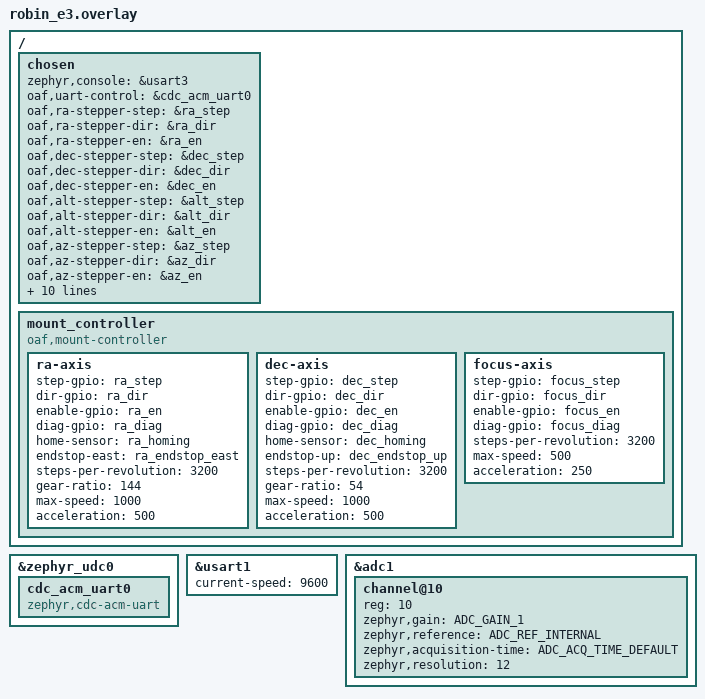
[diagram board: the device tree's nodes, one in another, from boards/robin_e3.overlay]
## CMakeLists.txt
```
cmake_minimum_required(VERSION 3.20.0)

find_package(Zephyr REQUIRED HINTS $ENV{ZEPHYR_BASE})
project(OpenAstroFirmware)

add_subdirectory_ifdef(CONFIG_MOUNT src/mount)

target_sources(app PRIVATE src/main.cpp)
```

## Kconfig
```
module = APP
module-str = app
source "subsys/logging/Kconfig.template.log_config"

rsource "src/mount/Kconfig"

menu "Zephyr"
source "Kconfig.zephyr"
endmenu
```

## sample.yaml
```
# This file is provided so that the application can be compiled using Twister,
# the Zephyr testing tool. In this file, multiple combinations can be specified,
# so that you can easily test all of them locally or in CI.
sample:
  description: OpenAstroFirmware
  name: openastrofirmware
common:
  build_only: true
  integration_platforms:
    - robin_nano
    - robin_e3
    - native_sim
tests:
  app.default: {}
  app.debug:
    extra_overlay_confs:
      - debug.conf
```

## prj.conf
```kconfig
# Disable zephyr log message at the beginning of the boot process
CONFIG_BOOT_BANNER=n

# C++ support
CONFIG_CPP=y
CONFIG_STD_CPP20=y
CONFIG_REQUIRES_FULL_LIBCPP=y

# GPIO support
CONFIG_GPIO=y

# CONFIG_RING_BUFFER=y
CONFIG_LX200=y

# CONFIG_TIMING_FUNCTIONS=y
CONFIG_MAIN_THREAD_PRIORITY=5

CONFIG_MAIN_STACK_SIZE=4096
CONFIG_HEAP_MEM_POOL_SIZE=4096

# Enable zephyr bus
CONFIG_ZBUS=y
CONFIG_ZBUS_MSG_SUBSCRIBER=y

# Stepper
# CONFIG_POLL=y
# CONFIG_COUNTER=y
# CONFIG_STEPPER=y
# CONFIG_STEP_DIR_STEPPER_COUNTER_TIMING=y

### Logging

CONFIG_LOG=y
CONFIG_LOG_BACKEND_UART=y
CONFIG_LOG_MODE_DEFERRED=y
# CONFIG_LOG_MODE_IMMEDIATE=y

# Default log level (including zephyr)
CONFIG_LOG_DEFAULT_LEVEL=3

# Serial
CONFIG_SERIAL=y

# Console
CONFIG_CONSOLE=y
# CONFIG_CONSOLE_SUBSYS=y
# CONFIG_CONSOLE_GETCHAR=y
# CONFIG_CONSOLE_GETCHAR_BUFSIZE=64
# CONFIG_CONSOLE_PUTCHAR_BUFSIZE=512

CONFIG_LOG_THREAD_ID_PREFIX=y

# Enables runtime filtering for logging.
# This allows the logging level to be changed at runtime,
# providing flexibility for debugging and monitoring.
# CONFIG_LOG_RUNTIME_FILTERING=y
# CONFIG_LOG_BUFFER_SIZE=4096
# CONFIG_LOG_PRINTK=y
# CONFIG_LOG_PROCESS_TRIGGER_THRESHOLD=0
# CONFIG_LOG_TAG_MAX_LEN=8

# Thread analyzer
# CONFIG_THREAD_ANALYZER=y
# CONFIG_THREAD_ANALYZER_USE_PRINTK=y 
# CONFIG_THREAD_ANALYZER_AUTO=y
# CONFIG_THREAD_ANALYZER_AUTO_INTERVAL=5

# Enable fault handling
# CONFIG_FAULT_DUMP=2
# CONFIG_EXCEPTION_STACK_TRACE=y
# CONFIG_DEBUG_COREDUMP=y 
# CONFIG_DEBUG_COREDUMP_BACKEND_LOGGING=y
# CONFIG_DEBUG_COREDUMP_MEMORY_DUMP_MIN=y
```

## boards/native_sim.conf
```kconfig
CONFIG_SERIAL=y

# CONFIG_UART_CONSOLE=y

# Enable the native POSIX UART driver backend
CONFIG_UART_NATIVE_POSIX=y

# Console (logs) will be on stdout
# CONFIG_UART_NATIVE_PTY_0_ON_STDINOUT=y
# CONFIG_NATIVE_UART_0_ON_STDINOUT=y

# Enable UART for control (e.g. lx200)
CONFIG_UART_NATIVE_POSIX_PORT_1_ENABLE=y
```

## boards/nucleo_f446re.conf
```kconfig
CONFIG_SYS_CLOCK_HW_CYCLES_PER_SEC=180000000
CONFIG_CORTEX_M_SYSTICK=y

CONFIG_UART_INTERRUPT_DRIVEN=y
CONFIG_UART_USE_RUNTIME_CONFIGURE=y

# CONFIG_USB_DEVICE_STACK=y
# CONFIG_USB_DEVICE_INITIALIZE_AT_BOOT=n
# CONFIG_USB_DEVICE_VID=0x1209
# CONFIG_USB_DEVICE_PID=0x0AF0
# CONFIG_USB_DEVICE_PRODUCT="OpenAstroFirmware"
# CONFIG_USB_DEVICE_MANUFACTURER="OpenAstroTech"

# CONFIG_USB_CDC_ACM=y
# CONFIG_USB_CDC_ACM_RINGBUF_SIZE=512

# CONFIG_USB_COMPOSITE_DEVICE=y

# # CONFIG_USB_DEVICE_LOG_LEVEL_INF=y
# # CONFIG_USB_DRIVER_LOG_LEVEL_INF=y
# CONFIG_USB_CDC_ACM_LOG_LEVEL_OFF=y
```

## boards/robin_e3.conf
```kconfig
CONFIG_SYS_CLOCK_HW_CYCLES_PER_SEC=72000000
CONFIG_CORTEX_M_SYSTICK=y

CONFIG_USB_DEVICE_STACK=y
CONFIG_USB_DEVICE_INITIALIZE_AT_BOOT=n
CONFIG_USB_DEVICE_VID=0x1209
CONFIG_USB_DEVICE_PID=0x0AF0
CONFIG_USB_DEVICE_PRODUCT="OpenAstroFirmware"
CONFIG_USB_DEVICE_MANUFACTURER="OpenAstroTech"

CONFIG_USB_CDC_ACM=y
CONFIG_USB_CDC_ACM_RINGBUF_SIZE=512

CONFIG_USB_COMPOSITE_DEVICE=y

# CONFIG_USB_DEVICE_LOG_LEVEL_INF=y
# CONFIG_USB_DRIVER_LOG_LEVEL_INF=y
CONFIG_USB_CDC_ACM_LOG_LEVEL_OFF=y
```

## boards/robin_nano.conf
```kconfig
CONFIG_SYS_CLOCK_HW_CYCLES_PER_SEC=168000000
CONFIG_CORTEX_M_SYSTICK=y

CONFIG_USB_DEVICE_STACK=y
CONFIG_USB_DEVICE_INITIALIZE_AT_BOOT=n
CONFIG_USB_DEVICE_VID=0x1209
CONFIG_USB_DEVICE_PID=0x0AF0
CONFIG_USB_DEVICE_PRODUCT="OpenAstroFirmware"
CONFIG_USB_DEVICE_MANUFACTURER="OpenAstroTech"

CONFIG_USB_CDC_ACM=y
CONFIG_USB_CDC_ACM_RINGBUF_SIZE=512

CONFIG_USB_COMPOSITE_DEVICE=y

# CONFIG_USB_DEVICE_LOG_LEVEL_INF=y
# CONFIG_USB_DRIVER_LOG_LEVEL_INF=y
CONFIG_USB_CDC_ACM_LOG_LEVEL_OFF=y
```

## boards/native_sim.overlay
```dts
/ {
    chosen {
        zephyr,console = &uart0;
        oaf,uart-control = &uart1;
    };
};

&uart0 {
    status = "okay";
};

&uart1 {
    status = "okay";
};
```

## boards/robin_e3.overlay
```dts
/ {
    chosen {
        // Console and control interfaces
        zephyr,console = &usart3; 
        oaf,uart-control = &cdc_acm_uart0;
        
        // OpenAstroFirmware specific device mappings
        oaf,ra-stepper-step = &ra_step;
        oaf,ra-stepper-dir = &ra_dir;
        oaf,ra-stepper-en = &ra_en;
        oaf,dec-stepper-step = &dec_step;
        oaf,dec-stepper-dir = &dec_dir;
        oaf,dec-stepper-en = &dec_en;
        oaf,alt-stepper-step = &alt_step;
        oaf,alt-stepper-dir = &alt_dir;
        oaf,alt-stepper-en = &alt_en;
        oaf,az-stepper-step = &az_step;
        oaf,az-stepper-dir = &az_dir;
        oaf,az-stepper-en = &az_en;
        oaf,focus-stepper-step = &focus_step;
        oaf,focus-stepper-dir = &focus_dir;
        oaf,focus-stepper-en = &focus_en;
        
        // Sensor mappings
        oaf,ra-home-sensor = &ra_homing;
        oaf,dec-home-sensor = &dec_homing;
        oaf,ra-endstop-east = &ra_endstop_east;
        oaf,dec-endstop-up = &dec_endstop_up;
        
        
        // Communication interfaces
        oaf,gps-uart = &usart1;
        oaf,external-i2c = &i2c1;
        
        // Status LED
        oaf,status-led = &status_led;
    };

    /* Mount Control Configuration */
    mount_controller {
        compatible = "oaf,mount-controller";
        
        /* RA Axis Configuration */
        ra-axis {
            step-gpio = <&ra_step>;
            dir-gpio = <&ra_dir>;
            enable-gpio = <&ra_en>;
            diag-gpio = <&ra_diag>;
            home-sensor = <&ra_homing>;
            endstop-east = <&ra_endstop_east>;
            
            steps-per-revolution = <3200>;
            gear-ratio = <144>;
            max-speed = <1000>;
            acceleration = <500>;
        };
        
        /* DEC Axis Configuration */
        dec-axis {
            step-gpio = <&dec_step>;
            dir-gpio = <&dec_dir>;
            enable-gpio = <&dec_en>;
            diag-gpio = <&dec_diag>;
            home-sensor = <&dec_homing>;
            endstop-up = <&dec_endstop_up>;
            
            steps-per-revolution = <3200>;
            gear-ratio = <54>;
            max-speed = <1000>;
            acceleration = <500>;
        };
        
        /* Focus/Alt Configuration */
        focus-axis {
            step-gpio = <&focus_step>;
            dir-gpio = <&focus_dir>;
            enable-gpio = <&focus_en>;
            diag-gpio = <&focus_diag>;
            
            steps-per-revolution = <3200>;
            max-speed = <500>;
            acceleration = <250>;
        };
        
        status = "okay";
    };

};

// Configuration for the CDC ACM UART
&zephyr_udc0 {
    cdc_acm_uart0: cdc_acm_uart0 {
        compatible = "zephyr,cdc-acm-uart";
    };
};

// GPS UART configuration
&usart1 {
    current-speed = <9600>;
    status = "okay";
};

// Additional ADC channel for LCD keypad
&adc1 {
    #address-cells = <1>;
    #size-cells = <0>;
    
    channel@10 {
        reg = <10>;
        zephyr,gain = "ADC_GAIN_1";
        zephyr,reference = "ADC_REF_INTERNAL";
        zephyr,acquisition-time = <ADC_ACQ_TIME_DEFAULT>;
        zephyr,resolution = <12>;
    };
};
```

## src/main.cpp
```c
#include <zephyr/kernel.h>
#include <zephyr/logging/log.h>

#include <mount/Mount.hpp>

LOG_MODULE_REGISTER(main, CONFIG_APP_LOG_LEVEL);

// Mount
Mount mount;

int main()
{

	// ReSharper disable CppDFAEndlessLoop
	while (true)
	// ReSharper restore CppDFAEndlessLoop
	{
		k_sleep(K_MSEC(100));
	}

	return 0;
}
```
